VERSION ""

NS_ :

BS_:

BU_:

BO_ 709 IDM_1: 8 Vector__XXX
 SG_ IDM_IntelliDriveModeReq_BCM : 0|1@0+ (1,0) [1|0] "" Vector__XXX
 SG_ IDM_ParkLightReq : 1|1@0+ (1,0) [1|0] "" Vector__XXX
 SG_ IDM_DRLReq : 2|1@0+ (1,0) [1|0] "" Vector__XXX
 SG_ IDM_LowBeamReq : 3|1@0+ (1,0) [1|0] "" Vector__XXX
 SG_ IDM_HighBeamReq : 4|1@0+ (1,0) [1|0] "" Vector__XXX
 SG_ IDM_FrontFogReq : 5|1@0+ (1,0) [1|0] "" Vector__XXX
 SG_ IDM_ReqrFogReq : 6|1@0+ (1,0) [1|0] "" Vector__XXX
 SG_ IDM_BrakeLightReq : 7|1@0+ (1,0) [1|0] "" Vector__XXX
 SG_ IDM_ReverseLightReq : 8|1@0+ (1,0) [1|0] "" Vector__XXX
 SG_ IDM_HornReq : 9|1@0+ (1,0) [1|0] "" Vector__XXX
 SG_ IDM_TurnLightReq_L : 10|1@0+ (1,0) [1|0] "" Vector__XXX
 SG_ IDM_TurnLightReq_R : 11|1@0+ (1,0) [1|0] "" Vector__XXX
 SG_ IDM_HazardLightReq : 12|1@0+ (1,0) [1|0] "" Vector__XXX
 SG_ IDM_WiperReq : 13|3@0+ (1,0) [7|0] "" Vector__XXX
 SG_ IDM_BuzzerRateReq : 16|2@0+ (1,0) [7|0] "" Vector__XXX
 SG_ IDM_DOWLightReq_FL : 18|2@0+ (1,0) [7|0] "" Vector__XXX
 SG_ IDM_DOWLightReq_FR : 20|2@0+ (1,0) [7|0] "" Vector__XXX
 SG_ IDM_DOWLightReq_RL : 22|2@0+ (1,0) [7|0] "" Vector__XXX
 SG_ IDM_DOWLightReq_RR : 24|2@0+ (1,0) [7|0] "" Vector__XXX

BO_ 339 VCU_12: 8 Vector__XXX
 SG_ VCU_VehActDriveMode : 2|3@0+ (1,0) [7|0] "" Vector__XXX
 SG_ VCU_VehActCtrlMode : 5|3@0+ (1,0) [7|0] "" Vector__XXX
 SG_ VCU_MaxAvailableTorq : 21|13@0+ (0.05,0) [300|0] "Nm" Vector__XXX
 SG_ VCU_MaxElecBrakeTorq : 24|13@0+ (0.05,-300) [0|-300] "Nm" Vector__XXX
 SG_ VCU_ActTorq : 40|14@0+ (0.05,-300) [300|-300] "Nm" Vector__XXX
 SG_ VCU_MsgCounter : 56|4@0+ (1,0) [15|0] "" Vector__XXX
 SG_ VCU_ActAccele : 60|12@0+ (0.01,-20.48) [20.46|-20.48] "m/s2" Vector__XXX

BO_ 545 VCU_ABS_4: 8 Vector__XXX
 SG_ ESC_YawRateValue : 12|12@0+ (0.05,-100) [104.7|-100] "deg/Sec." Vector__XXX
 SG_ ESC_LongitudinalAcceleration : 16|12@0+ (0.01,-20.48) [20.46|-20.48] "m/s2" Vector__XXX
 SG_ ESC_YawRateValue_VD : 32|1@0+ (1,0) [1|0] "" Vector__XXX
 SG_ ESC_LongitudinalAcceleration_VD : 33|1@0+ (1,0) [1|0] "" Vector__XXX
 SG_ ESC_LaterAccSensor_VD : 34|1@0+ (1,0) [1|0] "" Vector__XXX
 SG_ ESC_LaterAccSensor : 36|12@0+ (0.01,-20.48) [20.46|-20.48] "m/s2" Vector__XXX

BO_ 289 ACM_3: 8 Vector__XXX
 SG_ ACM_VehDriveModeReq : 0|3@0+ (1,0) [7|0] "" Vector__XXX
 SG_ ACM_VehCtrlModeReq : 3|3@0+ (1,0) [7|0] "" Vector__XXX
 SG_ ACM_IntelliDriveModeReq_Lengthwise : 6|1@0+ (1,0) [1|0] "" Vector__XXX
 SG_ ACM_BrakeReq : 8|1@0+ (1,0) [1|0] "" Vector__XXX
 SG_ ACM_EmergencyBrake : 9|1@0+ (1,0) [1|0] "" Vector__XXX
 SG_ ACM_EPBReq : 10|2@0+ (1,0) [3|0] "" Vector__XXX
 SG_ ACM_GearReq : 12|4@0+ (1,0) [15|0] "" Vector__XXX
 SG_ ACM_TorqReq : 24|16@0+ (0.05,-300) [300|-300] "Nm" Vector__XXX
 SG_ ACM_MotorSpdReq : 40|16@0+ (0.5,-12000) [12000|-12000] "rpm" Vector__XXX
 SG_ ACM_AcceleReq : 60|12@0+ (0.01,-20.48) [20.46|-20.48] "m/s2" Vector__XXX

BO_ 453 IDM_2: 8 Vector__XXX
 SG_ IDM_GearReq : 0|4@0+ (1,0) [15|0] "" Vector__XXX
 SG_ IDM_EPBReq : 4|2@0+ (1,0) [3|0] "" Vector__XXX
 SG_ IDM_EmergencyBrakeReq : 6|1@0+ (1,0) [1|0] "" Vector__XXX
 SG_ IDM_APAModeSts : 7|1@0+ (1,0) [1|0] "" Vector__XXX
 SG_ IDM_VehSpdReq : 21|11@0+ (0.05,0) [100|0] "km/h" Vector__XXX
 SG_ IDM_TorqReq : 24|13@0+ (0.1,-300) [300|-300] "Nm" Vector__XXX
 SG_ IDM_SteeringAngleReq : 40|16@0+ (0.1,-1080) [1080|-1080] "deg" Vector__XXX
 SG_ IDM_IntelliDriveModeReq_Lateral : 52|1@0+ (1,0) [1|0] "" Vector__XXX
 SG_ IDM_IntelliDriveModeReq_Lengthwise : 53|1@0+ (1,0) [1|0] "" Vector__XXX
 SG_ IDM_VehCtrlModeReq : 54|2@0+ (1,0) [3|0] "" Vector__XXX
 SG_ IDM_AcceleReq : 56|12@0+ (0.01,-20.48) [20.46|-20.48] "m/s2" Vector__XXX

BO_ 338 VCU_11: 8 Vector__XXX
 SG_ VCU_TargetGear : 0|4@0+ (1,0) [15|0] "" Vector__XXX
 SG_ VCU_ActGear : 4|4@0+ (1,0) [15|0] "" Vector__XXX
 SG_ VCU_AccelPedalPosition : 8|8@0+ (0.4,0) [100|0] "%" Vector__XXX
 SG_ VCU_BrakePedalSts : 16|1@0+ (1,0) [1|0] "" Vector__XXX
 SG_ VCU_AccelPedal_VD : 17|1@0+ (1,0) [1|0] "" Vector__XXX
 SG_ VCU_BrakePedal_VD : 18|1@0+ (1,0) [1|0] "" Vector__XXX
 SG_ VCU_TargetGear_VD : 19|1@0+ (1,0) [1|0] "" Vector__XXX
 SG_ VCU_ActGear_VD : 20|1@0+ (1,0) [1|0] "" Vector__XXX
 SG_ VCU_ReadySts : 21|1@0+ (1,0) [1|0] "" Vector__XXX
 SG_ VCU_ImmobileEPBReq : 22|2@0+ (1,0) [3|0] "" Vector__XXX
 SG_ VCU_DynamicEPBReq : 29|1@0+ (1,0) [1|0] "" Vector__XXX
 SG_ VCU_ElecBrake_EnableSts : 30|1@0+ (1,0) [1|0] "" Vector__XXX
 SG_ VCU_ImmobileEPBReq_VD : 31|1@0+ (1,0) [1|0] "" Vector__XXX
 SG_ VCU_VehSpd : 32|13@0+ (0.0625,0) [512|0] "km/h" Vector__XXX
 SG_ VCU_SlopeGradient_VD : 40|1@0+ (1,0) [1|0] "" Vector__XXX
 SG_ VCU_SlopeGradient : 48|8@0+ (0.1,-10) [10|-10] "m/s2" Vector__XXX

BO_ 1040 VCU_MCU_1: 8 Vector__XXX
 SG_ MCU_MotorSpd : 24|16@0+ (0.5,-12000) [12000|-12000] "rpm" Vector__XXX
 SG_ MCU_ActTorq : 40|16@0+ (0.05,-300) [300|-300] "Nm" Vector__XXX

BO_ 710 IDM_4: 8 Vector__XXX
 SG_ IDM__AEB_EnableSts : 0|2@0+ (1,0) [3|0] "" Vector__XXX
 SG_ IDM__FCW_EnableSts : 2|2@0+ (1,0) [3|0] "" Vector__XXX
 SG_ IDM__LDW_EnableSts : 4|2@0+ (1,0) [3|0] "" Vector__XXX
 SG_ IDM__LCK_EnableSts : 6|2@0+ (1,0) [3|0] "" Vector__XXX
 SG_ IDM__TJA_EnableSts : 8|2@0+ (1,0) [3|0] "" Vector__XXX
 SG_ IDM__LimSpdEnableSts : 10|2@0+ (1,0) [3|0] "" Vector__XXX
 SG_ IDM__AutoHighLamp_EnableSts : 12|2@0+ (1,0) [3|0] "" Vector__XXX
 SG_ IDM__BSD_EnableSts : 14|2@0+ (1,0) [3|0] "" Vector__XXX
 SG_ IDM__DOW_EnableSts : 16|2@0+ (1,0) [3|0] "" Vector__XXX
 SG_ IDM__RCW_EnableSts : 18|2@0+ (1,0) [3|0] "" Vector__XXX
 SG_ IDM__RCTA_EnableSts : 20|2@0+ (1,0) [3|0] "" Vector__XXX
 SG_ IDM__LDW_SensSts : 22|2@0+ (1,0) [3|0] "" Vector__XXX
 SG_ IDM__AHC_Dist_SetSts : 28|2@0+ (1,0) [3|0] "" Vector__XXX
 SG_ IDM__BSD_WarnSwSts : 30|2@0+ (1,0) [3|0] "" Vector__XXX
 SG_ IDM__FCW_WarnSwSts : 32|2@0+ (1,0) [3|0] "" Vector__XXX
 SG_ IDM__DOW_WarnSwSts : 34|2@0+ (1,0) [3|0] "" Vector__XXX
 SG_ IDM__RCTA_WarnSwSts : 36|2@0+ (1,0) [3|0] "" Vector__XXX
 SG_ IDM_APA_EnableSts : 38|2@0+ (1,0) [3|0] "" Vector__XXX

BO_ 1129 VCU_BMS_1: 8 Vector__XXX
 SG_ BMS_SOC_Disp : 40|16@0+ (0.01,0) [100|0] "%" Vector__XXX

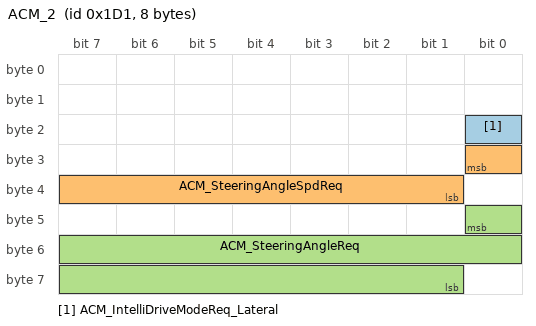
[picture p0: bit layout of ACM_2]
BO_ 465 ACM_2: 8 Vector__XXX
 SG_ ACM_IntelliDriveModeReq_Lateral : 16|1@0+ (1,0) [1|0] "" Vector__XXX
 SG_ ACM_SteeringAngleSpdReq : 24|8@0+ (4,0) [1016|0] "deg/Sec." Vector__XXX
 SG_ ACM_SteeringAngleReq : 40|16@0+ (0.1,-1080) [1080|-1080] "deg" Vector__XXX

BO_ 469 EPS_1: 8 Vector__XXX
 SG_ EPS_AutoCtrlModeSts : 0|1@0+ (1,0) [1|0] "" Vector__XXX
 SG_ EPS_ManualCtrlDetectionSts : 1|1@0+ (1,0) [1|0] "" Vector__XXX
 SG_ EPS_SystemFaultSts : 7|1@0+ (1,0) [1|0] "" Vector__XXX
 SG_ EPS_SteeringAngle : 16|16@0+ (0.1,-1080) [1080|-1080] "deg" Vector__XXX
 SG_ EPS_SteeringAngleSpd : 24|8@0+ (4,0) [1016|0] "deg/Sec." Vector__XXX

BO_ 337 VCU_8: 8 Vector__XXX
 SG_ VCU_TargetGear : 0|4@0+ (1,0) [15|0] "" Vector__XXX
 SG_ VCU_ActGear : 4|4@0+ (1,0) [15|0] "" Vector__XXX
 SG_ VCU_AccelPedalPosition : 8|8@0+ (0.4,0) [100|0] "%" Vector__XXX
 SG_ VCU_BrakePedalSts : 16|1@0+ (1,0) [1|0] "" Vector__XXX
 SG_ VCU_AccelPedal_VD : 17|1@0+ (1,0) [1|0] "" Vector__XXX
 SG_ VCU_BrakePedal_VD : 18|1@0+ (1,0) [1|0] "" Vector__XXX
 SG_ VCU_TargetGear_VD : 19|1@0+ (1,0) [1|0] "" Vector__XXX
 SG_ VCU_ActGear_VD : 20|1@0+ (1,0) [1|0] "" Vector__XXX
 SG_ VCU_ReadySts : 21|1@0+ (1,0) [1|0] "" Vector__XXX
 SG_ VCU_AutoCtrlModeSts : 22|1@0+ (1,0) [1|0] "" Vector__XXX
 SG_ VCU_VehGradient : 40|8@0+ (0.1,-10) [10|-10] "m/s2" Vector__XXX

BO_ 792 VCU_ABS_2: 8 Vector__XXX
 SG_ ABS_EBDFaultSts : 8|1@0+ (1,0) [1|0] "" Vector__XXX
 SG_ ABS_ESCEnableSwSts : 9|1@0+ (1,0) [1|0] "" Vector__XXX
 SG_ ABS_ABSFaultSts : 10|1@0+ (1,0) [1|0] "" Vector__XXX
 SG_ ABS_AEBActiveSts : 11|1@0+ (1,0) [1|0] "" Vector__XXX
 SG_ ABS_AEBAvailableSts : 12|1@0+ (1,0) [1|0] "" Vector__XXX
 SG_ ABS_ABSActiveSts : 13|1@0+ (1,0) [1|0] "" Vector__XXX
 SG_ ABS_ESCFaultSts : 14|1@0+ (1,0) [1|0] "" Vector__XXX
 SG_ ABS_BrakePedalActiveSts : 15|1@0+ (1,0) [1|0] "" Vector__XXX
 SG_ ABS_EPBBrakeReq : 16|1@0+ (1,0) [1|0] "" Vector__XXX
 SG_ ABS_EBDWarnLamp : 17|1@0+ (1,0) [1|0] "" Vector__XXX
 SG_ ABS_ABSWarnLamp : 18|1@0+ (1,0) [1|0] "" Vector__XXX
 SG_ ABS_CarbonBrushFaulSts : 19|1@0+ (1,0) [1|0] "" Vector__XXX
 SG_ ABS_ACCControlActiveSts : 20|1@0+ (1,0) [1|0] "" Vector__XXX
 SG_ ABS_CurrentConfiguration : 21|1@0+ (1,0) [1|0] "" Vector__XXX
 SG_ ABS_ACCControlAvailableSts : 22|1@0+ (1,0) [1|0] "" Vector__XXX
 SG_ ABS_VehSpd_VD : 23|1@0+ (1,0) [1|0] "" Vector__XXX
 SG_ ABS_VehSpd : 32|16@0+ (0.01,0) [655.34|0] "km/h" Vector__XXX

BO_ 456 IDM_3: 8 Vector__XXX
 SG_ IDM_SteeringAngleSpdReq : 0|8@0+ (4,0) [1016|0] "deg/Sec." Vector__XXX
 SG_ IDM_DeceleReq : 16|12@0+ (0.01,-20.48) [20.46|-20.48] "m/s2" Vector__XXX
 SG_ IDM_MsgCounter : 56|4@0+ (1,0) [15|0] "" Vector__XXX

BO_ 793 VCU_ABS_3: 8 Vector__XXX
 SG_ ABS_WheelSpd_FL_Pulse : 0|8@0+ (1,0) [255|0] "" Vector__XXX
 SG_ ABS_WheelSpd_FL_Pulse_VD : 15|1@0+ (1,0) [1|0] "" Vector__XXX
 SG_ ABS_WheelSpd_FR_Pulse : 16|8@0+ (1,0) [255|0] "" Vector__XXX
 SG_ ABS_WheelSpd_FR_Pulse_VD : 31|1@0+ (1,0) [1|0] "" Vector__XXX
 SG_ ABS_WheelSpd_RL_Pulse : 32|8@0+ (1,0) [255|0] "" Vector__XXX
 SG_ ABS_WheelSpd_RL_Pulse_VD : 47|1@0+ (1,0) [1|0] "" Vector__XXX
 SG_ ABS_WheelSpd_RR_Pulse : 48|8@0+ (1,0) [255|0] "" Vector__XXX
 SG_ ABS_WheelSpd_RR_Pulse_VD : 63|1@0+ (1,0) [1|0] "" Vector__XXX

BO_ 914 VCU_BCM_1: 8 Vector__XXX
 SG_ BCM_KeySts : 0|2@0+ (1,0) [3|0] "" Vector__XXX
 SG_ BCM_TurnLightSts_R : 2|1@0+ (1,0) [1|0] "" Vector__XXX
 SG_ BCM_TurnLightSts_L : 3|1@0+ (1,0) [1|0] "" Vector__XXX
 SG_ BCM_HazardLightSts : 4|1@0+ (1,0) [1|0] "" Vector__XXX
 SG_ BCM_ParkingLightSts : 5|1@0+ (1,0) [1|0] "" Vector__XXX
 SG_ BCM_HighBeamSts : 6|1@0+ (1,0) [1|0] "" Vector__XXX
 SG_ BCM_LowBeamSts : 7|1@0+ (1,0) [1|0] "" Vector__XXX
 SG_ BCM_DRLSts : 8|1@0+ (1,0) [1|0] "" Vector__XXX
 SG_ BCM_DoorAjarSts_Driver : 9|1@0+ (1,0) [1|0] "" Vector__XXX
 SG_ BCM_DoorAjarSts_Psngr : 10|1@0+ (1,0) [1|0] "" Vector__XXX
 SG_ BCM_DoorAjarSts_RR : 11|1@0+ (1,0) [1|0] "" Vector__XXX
 SG_ BCM_DoorAjarSts_RL : 12|1@0+ (1,0) [1|0] "" Vector__XXX
 SG_ BCM_TrunkAjarSts : 13|1@0+ (1,0) [1|0] "" Vector__XXX
 SG_ BCM_TrunkReleaseReq : 14|1@0+ (1,0) [1|0] "" Vector__XXX
 SG_ BCM_RearFogLightSts : 15|1@0+ (1,0) [1|0] "" Vector__XXX
 SG_ BCM_ACC_RelaySts : 18|1@0+ (1,0) [1|0] "" Vector__XXX
 SG_ BCM_ON_RelaySts : 19|1@0+ (1,0) [1|0] "" Vector__XXX
 SG_ BCM_AntiTheftMode : 20|3@0+ (1,0) [7|0] "" Vector__XXX
 SG_ BCM_EmergencyStrat : 23|1@0+ (1,0) [1|0] "" Vector__XXX
 SG_ BCM_EmergencyStop : 24|2@0+ (1,0) [3|0] "" Vector__XXX
 SG_ BCM_GearboxPositionSts : 26|1@0+ (1,0) [1|0] "" Vector__XXX
 SG_ BCM_VehStartEnableSts : 27|1@0+ (1,0) [1|0] "" Vector__XXX
 SG_ BCM_IGN_CtrlSource : 28|4@0+ (1,0) [15|0] "" Vector__XXX
 SG_ BCM_12V_BattVolt : 32|8@0+ (0.1,0) [25.4|0] "V" Vector__XXX
 SG_ BCM_DoorLockSts_Driver : 40|1@0+ (1,0) [1|0] "" Vector__XXX
 SG_ BCM_VehOperationInd : 41|3@0+ (1,0) [7|0] "" Vector__XXX
 SG_ BCM_DoorLockSts_Trunk : 44|1@0+ (1,0) [1|0] "" Vector__XXX
 SG_ BCM_OTA_Sts : 46|2@0+ (1,0) [3|0] "" Vector__XXX
 SG_ BCM_WinPostionSts_FL : 48|3@0+ (1,0) [7|0] "" Vector__XXX
 SG_ BCM_WinPostionSts_FR : 51|3@0+ (1,0) [7|0] "" Vector__XXX
 SG_ BCM_SoftAntiTheftSts : 54|1@0+ (1,0) [1|0] "" Vector__XXX
 SG_ BCM_Reserved_VehRentalSts : 55|1@0+ (1,0) [1|0] "" Vector__XXX
 SG_ BCM_SW_Flag : 56|2@0+ (1,0) [1|0] "" Vector__XXX
 SG_ BCM_WiperSts : 58|3@0+ (1,0) [7|0] "" Vector__XXX
 SG_ BCM_TurnLightDirection_L : 61|1@0+ (1,0) [1|0] "" Vector__XXX
 SG_ BCM_TurnLightDirection_R : 62|1@0+ (1,0) [1|0] "" Vector__XXX

BO_ 1106 VCU_ICM_1: 8 Vector__XXX
 SG_ ICM_TotalOdometer : 32|20@0+ (1,0) [999999|0] "km" Vector__XXX
 SG_ ICM_DrvierSeatBeltSwSts : 41|1@0+ (1,0) [1|0] "" Vector__XXX

BO_ 561 EPB_1: 8 Vector__XXX
 SG_ EPB_ParkLampSts : 0|2@0+ (1,0) [3|0] "" Vector__XXX
 SG_ EPB_WarnLampSts : 2|2@0+ (1,0) [3|0] "" Vector__XXX
 SG_ EPB_SwSts : 4|2@0+ (1,0) [3|0] "" Vector__XXX
 SG_ EPB_ActuatorSts_L : 8|4@0+ (1,0) [15|0] "" Vector__XXX
 SG_ EPB_ActuatorSts_R : 12|4@0+ (1,0) [15|0] "" Vector__XXX
 SG_ EPB_BrakeLightReq : 16|1@0+ (1,0) [1|0] "" Vector__XXX
 SG_ EPB_DynamicBrakeSts : 17|3@0+ (1,0) [7|0] "" Vector__XXX
 SG_ EPB_WarningDisp_Brake : 20|1@0+ (1,0) [1|0] "" Vector__XXX
 SG_ EPB_FaultLevel : 24|2@0+ (1,0) [3|0] "" Vector__XXX
 SG_ EPB_MsgCounter : 52|4@0+ (1,0) [15|0] "" Vector__XXX
 SG_ EPB_Checksum : 56|8@0+ (1,0) [255|0] "" Vector__XXX

BO_ 721 ACM_0: 8 Vector__XXX
 SG_ ACM_AutomaticDriveModeReq : 0|1@0+ (1,0) [1|0] "" Vector__XXX

BO_ 290 ACM_4: 8 Vector__XXX
 SG_ ACM_ACC_ONSwSts : 2|1@0+ (1,0) [1|0] "" Vector__XXX
 SG_ ACM_ACC_OFFSwSts : 3|1@0+ (1,0) [1|0] "" Vector__XXX
 SG_ ACM_SpdLimReq : 8|10@0+ (0.1,0) [100|0] "km/h" Vector__XXX
 SG_ ACM_BrakeDeceleReq : 28|12@0+ (0.01,-20.48) [20.46|-20.48] "m/s2" Vector__XXX
 SG_ ACM_DriveDistanceReq : 32|12@0+ (0.01,-100) [100|-100] "m" Vector__XXX
 SG_ ACM_ChangeAccelerationReq : 48|16@0+ (0.001,-5) [5|-5] "m/s3" Vector__XXX
 SG_ ACM_MsgCounter : 56|4@0+ (1,0) [15|0] "" Vector__XXX

BO_ 768 VCU_ABS_1: 8 Vector__XXX
 SG_ ABS_WheelSpd_FL_VD : 6|2@0+ (1,0) [1|0] "" Vector__XXX
 SG_ ABS_WheelSpd_FL : 8|14@0+ (0.0625,0) [1023.875|0] "km/h" Vector__XXX
 SG_ ABS_WheelSpd_FR_VD : 22|2@0+ (1,0) [1|0] "" Vector__XXX
 SG_ ABS_WheelSpd_FR : 24|14@0+ (0.0625,0) [1023.875|0] "km/h" Vector__XXX
 SG_ ABS_WheelSpd_RL_VD : 38|2@0+ (1,0) [1|0] "" Vector__XXX
 SG_ ABS_WheelSpd_RL : 40|14@0+ (0.0625,0) [1023.875|0] "km/h" Vector__XXX
 SG_ ABS_WheelSpd_RR_VD : 54|2@0+ (1,0) [1|0] "" Vector__XXX
 SG_ ABS_WheelSpd_RR : 56|14@0+ (0.0625,0) [1023.875|0] "km/h" Vector__XXX

BA_DEF_  "BusType" STRING ;
BA_DEF_DEF_  "BusType" "CAN";
